# ESP32-C2 register map
Vendor: ESPRESSIF SYSTEMS (SHANGHAI) CO., LTD.; Series: ESP32 C-Series; File version: 11
CPU: RV32IMC r0p0, little endian, no MPU, no FPU, 0 interrupt priority bits
Address unit: 32 bits
Registers are 32-bit, read-write, reset 0x0 unless marked. A register's access mark holds for its fields unless they carry their own. Offsets are from the block's base; [hi:lo] are bit positions; {n}, {i} and the like mark numbered series; 'fields as' and 'values as' point back to an identical list.

## APB_SARADC — SAR (Successive Approximation Register) Analog-to-Digital Converter
Base 0x60040000
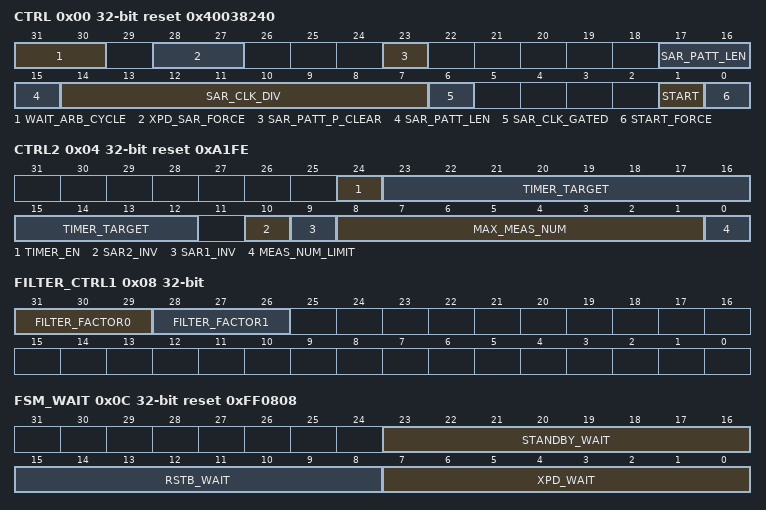
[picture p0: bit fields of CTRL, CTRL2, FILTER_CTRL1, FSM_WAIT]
0x00 CTRL reset 0x40038240 — register description
  [31:30] WAIT_ARB_CYCLE — wait arbit signal stable after sar_done
  [28:27] XPD_SAR_FORCE — force option to xpd sar blocks
  [23] SAR_PATT_P_CLEAR — clear the pointer of pattern table for DIG ADC1 CTRL
  [17:15] SAR_PATT_LEN — 0 ~ 15 means length 1 ~ 16
  [14:7] SAR_CLK_DIV — SAR clock divider
  [6] SAR_CLK_GATED — Need add description
  [1] START — Need add description
  [0] START_FORCE — Need add description
0x04 CTRL2 reset 0xA1FE — register description
  [24] TIMER_EN — to enable saradc timer trigger
  [23:12] TIMER_TARGET — to set saradc timer target
  [10] SAR2_INV — 1: data to DIG ADC2 CTRL is inverted, otherwise not
  [9] SAR1_INV — 1: data to DIG ADC1 CTRL is inverted, otherwise not
  [8:1] MAX_MEAS_NUM — max conversion number
  [0] MEAS_NUM_LIMIT — Need add description
0x08 FILTER_CTRL1 — register description
  [31:29] FILTER_FACTOR0 — Need add description
  [28:26] FILTER_FACTOR1 — Need add description
0x0C FSM_WAIT reset 0xFF0808 — register description
  [23:16] STANDBY_WAIT — Need add description
  [15:8] RSTB_WAIT — Need add description
  [7:0] XPD_WAIT — Need add description
0x10 SAR1_STATUS ro — register description
  [31:0] SAR1_STATUS — Need add description
0x14 SAR2_STATUS ro — register description
  [31:0] SAR2_STATUS — Need add description
0x18 SAR_PATT_TAB1 reset 0xFFFFFF — register description
  [23:0] SAR_PATT_TAB1 — item 0 ~ 3 for pattern table 1 (each item one byte)
0x1C SAR_PATT_TAB2 reset 0xFFFFFF — register description
  [23:0] SAR_PATT_TAB2 — Item 4 ~ 7 for pattern table 1 (each item one byte)
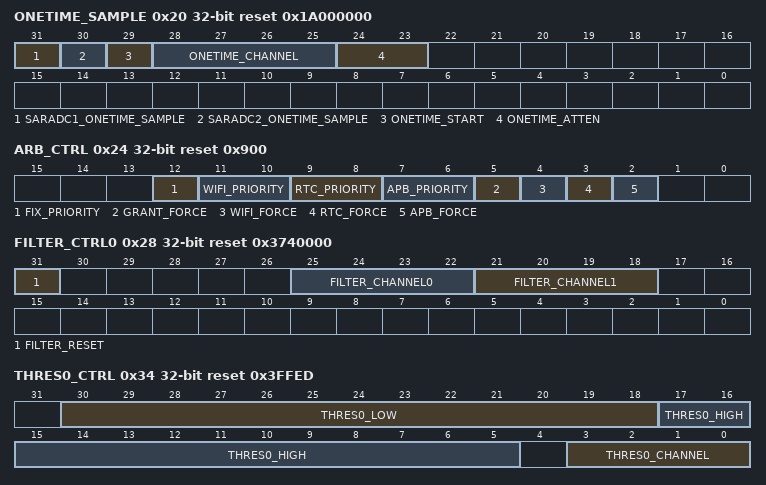
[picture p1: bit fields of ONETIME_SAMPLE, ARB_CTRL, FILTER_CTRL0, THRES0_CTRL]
0x20 ONETIME_SAMPLE reset 0x1A000000 — register description
  [31] SARADC1_ONETIME_SAMPLE — Need add description
  [30] SARADC2_ONETIME_SAMPLE — Need add description
  [29] ONETIME_START — Need add description
  [28:25] ONETIME_CHANNEL — Need add description
  [24:23] ONETIME_ATTEN — Need add description
0x24 ARB_CTRL reset 0x900 — register description
  [12] FIX_PRIORITY — adc2 arbiter uses fixed priority
  [11:10] WIFI_PRIORITY — Set adc2 arbiter wifi priority
  [9:8] RTC_PRIORITY — Set adc2 arbiter rtc priority
  [7:6] APB_PRIORITY — Set adc2 arbiterapb priority
  [5] GRANT_FORCE — adc2 arbiter force grant
  [4] WIFI_FORCE — adc2 arbiter force to enable wifi controller
  [3] RTC_FORCE — adc2 arbiter force to enable rtc controller
  [2] APB_FORCE — adc2 arbiter force to enableapb controller
0x28 FILTER_CTRL0 reset 0x3740000 — register description
  [31] FILTER_RESET — enable apb_adc1_filter
  [25:22] FILTER_CHANNEL0 — apb_adc1_filter_factor
  [21:18] FILTER_CHANNEL1 — Need add description
0x2C SAR1DATA_STATUS ro — register description
  [16:0] SARADC1_DATA — Need add description
0x30 SAR2DATA_STATUS ro — register description
  [16:0] SARADC2_DATA — Need add description
0x34 THRES0_CTRL reset 0x3FFED — register description
  [30:18] THRES0_LOW — saradc1's thres0 monitor thres
  [17:5] THRES0_HIGH — saradc1's thres0 monitor thres
  [3:0] THRES0_CHANNEL — Need add description
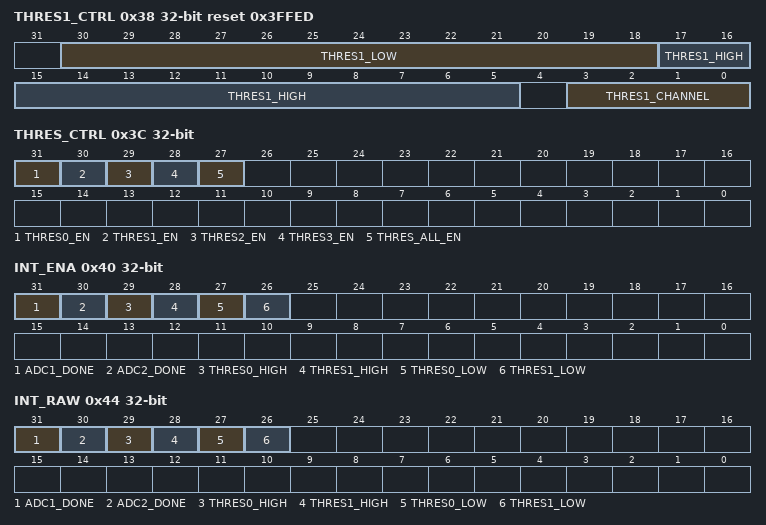
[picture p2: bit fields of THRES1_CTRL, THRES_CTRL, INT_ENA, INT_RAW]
0x38 THRES1_CTRL reset 0x3FFED — register description
  [30:18] THRES1_LOW — saradc1's thres0 monitor thres
  [17:5] THRES1_HIGH — saradc1's thres0 monitor thres
  [3:0] THRES1_CHANNEL — Need add description
0x3C THRES_CTRL — register description
  [31-n] THRES{n}_EN (n=0..3) — Need add description
  [27] THRES_ALL_EN — Need add description
0x40 INT_ENA — register description
  [31] ADC1_DONE — Need add description
  [30] ADC2_DONE — Need add description
  [29] THRES0_HIGH — Need add description
  [28] THRES1_HIGH — Need add description
  [27] THRES0_LOW — Need add description
  [26] THRES1_LOW — Need add description
0x44 INT_RAW ro — register description
  fields as INT_ENA
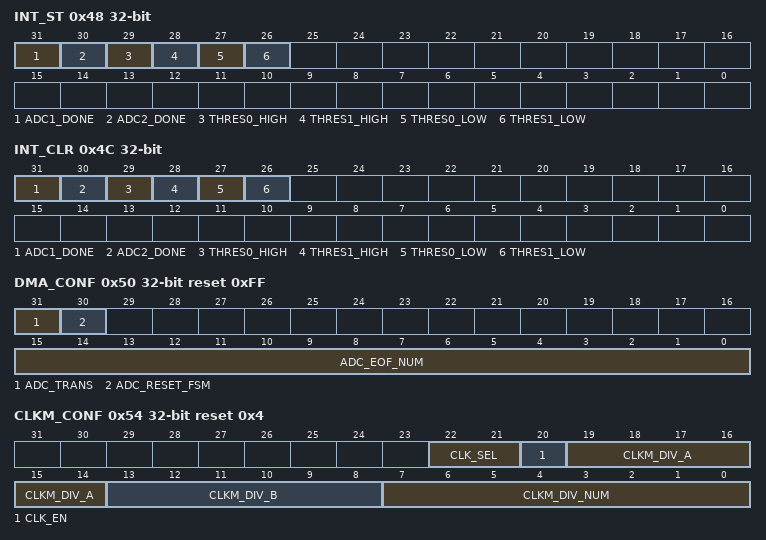
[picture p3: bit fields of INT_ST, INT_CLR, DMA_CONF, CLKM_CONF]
0x48 INT_ST ro — register description
  fields as INT_ENA
0x4C INT_CLR wo — register description
  [31] ADC1_DONE write-1-clears — Need add description
  [30] ADC2_DONE write-1-clears — Need add description
  [29] THRES0_HIGH write-1-clears — Need add description
  [28] THRES1_HIGH write-1-clears — Need add description
  [27] THRES0_LOW write-1-clears — Need add description
  [26] THRES1_LOW write-1-clears — Need add description
0x50 DMA_CONF reset 0xFF — register description
  [31] ADC_TRANS — enable apb_adc use spi_dma
  [30] ADC_RESET_FSM — reset_apb_adc_state
  [15:0] ADC_EOF_NUM — the dma_in_suc_eof gen when sample cnt = spi_eof_num
0x54 CLKM_CONF reset 0x4 — register description
  [22:21] CLK_SEL — Set this bit to enable clk_apll
  [20] CLK_EN — Need add description
  [19:14] CLKM_DIV_A — Fractional clock divider denominator value
  [13:8] CLKM_DIV_B — Fractional clock divider numerator value
  [7:0] CLKM_DIV_NUM — Integral I2S clock divider value
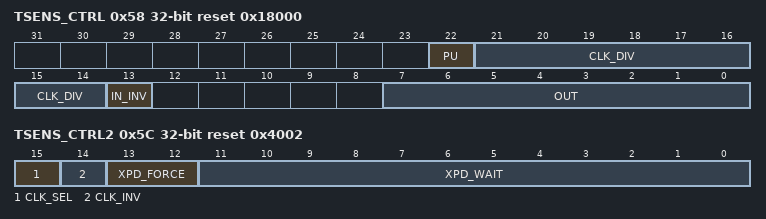
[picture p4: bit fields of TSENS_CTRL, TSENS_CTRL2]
0x58 TSENS_CTRL access per field reset 0x18000 — register description
  [22] PU rw — Need add description
  [21:14] CLK_DIV rw — Need add description
  [13] IN_INV rw — Need add description
  [7:0] OUT ro — Need add description
0x5C TSENS_CTRL2 reset 0x4002 — register description
  [15] CLK_SEL — Need add description
  [14] CLK_INV — Need add description
  [13:12] XPD_FORCE — Need add description
  [11:0] XPD_WAIT — Need add description
0x60 CALI reset 0x8000 — register description
  [16:0] CFG — Need add description
0x3FC CTRL_DATE — register description
